# K1921VK028 register map
Vendor: NIIET; Series: K1921VKx; File version: 2.17
CPU: CM4 r0p1, little endian, MPU, FPU, 4 interrupt priority bits
Registers are 32-bit, read-write, reset 0x0 unless marked. A register's access mark holds for its fields unless they carry their own. Offsets are from the block's base; [hi:lo] are bit positions; lines under a group give offsets from that group; {n}, {i} and the like mark numbered series; 'fields as' and 'values as' point back to an identical list.

## SDFM — SDFM controller registers
Base 0x40075000
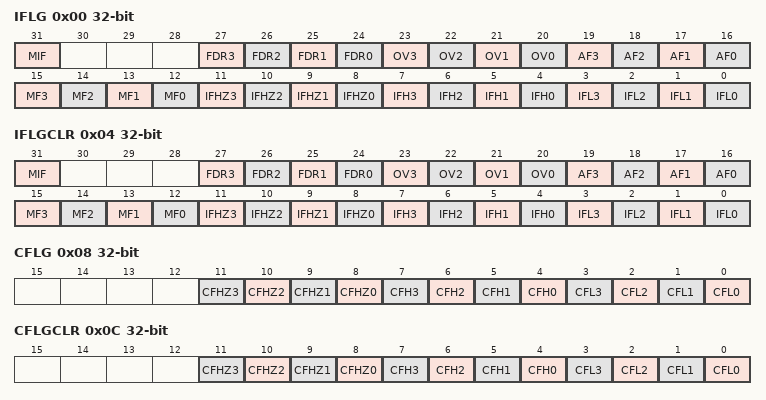
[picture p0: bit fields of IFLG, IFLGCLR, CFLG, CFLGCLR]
0x00 IFLG ro — Interrupt Flag Register
  [31] MIF — OR'ed flags OVx, MFx, IFHx, IFLx
  [n+24] FDR{n} (n=0..3) — FIFO{n} data ready flag
  [n+20] OV{n} (n=0..3) — Overflow FIFO{n} error flag
  [n+16] AF{n} (n=0..3) — New data available from filter {n}
  [n+12] MF{n} (n=0..3) — Modulator failure filter {n}
  [n+8] IFHZ{n} (n=0..3) — Comparator filter {n} output is equal to or above the zero level threshold
  [n+4] IFH{n} (n=0..3) — Comparator filter {n} output is equal to or above the high level threshold
  [n] IFL{n} (n=0..3) — Comparator filter {n} output is equal to or below the low level threshold
0x04 IFLGCLR wo — Clear Interrupt flag register
  [31] MIF — MIF flag clear bit
  [n+24] FDR{n} (n=0..3) — FIFO{n} data ready flag clear
  [n+20] OV{n} (n=0..3) — Overflow FIFO{n} error flag clear bit
  [n+16] AF{n} (n=0..3) — New data available from filter {n} clear bit
  [n+12] MF{n} (n=0..3) — Modulator failure filter {n} clear bit
  [n+8] IFHZ{n} (n=0..3) — Comparator filter {n} output is equal to or above the zero level threshold clear bit
  [n+4] IFH{n} (n=0..3) — Comparator filter {n} output is equal to or above the high level threshold clear bit
  [n] IFL{n} (n=0..3) — Comparator filter {n} output is equal to or below the low level threshold clear bit
0x08 CFLG ro — Comparator Flag Register
  [n+8] CFHZ{n} (n=0..3), [n+4] CFH{n} (n=0..3), [n] CFL{n} (n=0..3)
0x0C CFLGCLR wo — Comparator Flag Clear Register
  [n+8] CFHZ{n} (n=0..3), [n+4] CFH{n} (n=0..3), [n] CFL{n} (n=0..3)
0x10 CTL — Control Register
  [0] MIE — Master interrupt enable
0x14 MFILEN — Master Filter Enable Register
  [0] MFE — Master filter enable
{0x18+0x30*i} SD[{i}] (i=0..3) group
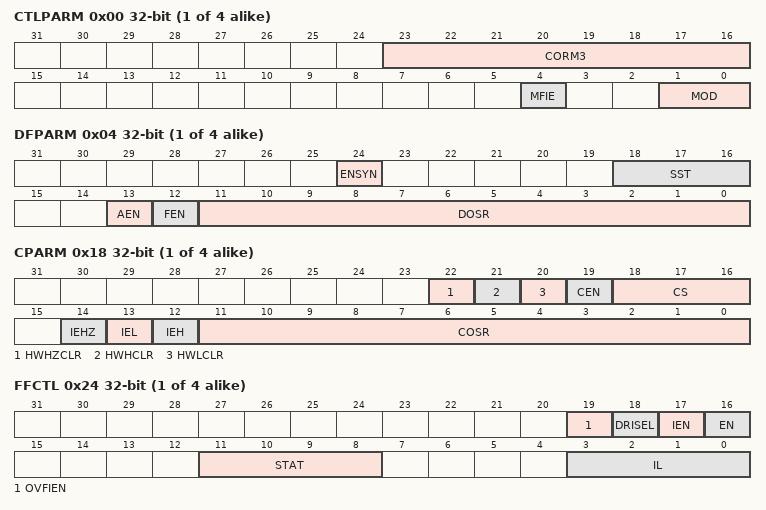
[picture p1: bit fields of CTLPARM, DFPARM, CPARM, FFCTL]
  0x00 CTLPARM — Filter Control Register
    [23:16] CORM3 — Clock out ratio for mode 3
    [4] MFIE — Modulator failure interrupt enable
    [1:0] MOD — Sigma Delta modulator IO mode
      0=Mode0SDR (single data rate); 1=Mode1DDR (double data rate); 2=Mode2Manchester (manchester coding); 3=Mode3HDR (half data rate)
  0x04 DFPARM — Data Filter Parameter Register
    [24] ENSYN — Enable syncronization for filter
    [18:16] SST — Data Filter structure
      0=FastSinc; 1=sinc 1-st order; 2=sinc 2-nd order; 3=sinc 3-rd order; 4=sinc 4-th order; 5=sinc 5-th order
    [13] AEN — Acknowledge enable
    [12] FEN — Filter enable
    [11:0] DOSR — Oversampling ratio
  0x08 DPARM — Shift Data Control Register
    [4:0] SH — Shift control
  0x0C CMPH — High Level Comparator Register
    [31:0] VAL — Unsigned high-level threshold comparator
  0x10 CMPHZ — Zero Level Comparator Register
    [31:0] VAL — Unsigned zero-level threshold comparator
  0x14 CMPL — Low Level Comparator Register
    [31:0] VAL — Unsigned low-level threshold comparator
  0x18 CPARM — Comparator Parameter register
    [22] HWHZCLR — Enable hardware clear zero threshold comparator exceed event
    [21] HWHCLR — Enable hardware clear high threshold comparator exceed event
    [20] HWLCLR — Enable hardware clear low threshold comparator exceed event
    [19] CEN — Comparator enable
    [18:16] CS — Comparator filter structure
      values as SD[0].DFPARM.SST
    [14] IEHZ — Zero-level interrupt enable
    [13] IEL — Low-level interrupt enable
    [12] IEH — High-level interrupt enable
    [11:0] COSR — Oversampling ratio for comparator
  0x1C DATA ro
    [31:0] VAL — Signed data value
  0x20 CDATA ro — Comparator Data Register
    [31:0] VAL — Comparator Data Value
  0x24 FFCTL — FIFO Configuration Register
    [19] OVFIEN — Overflow interrupt enable
    [18] DRISEL — Data Ready Int source
      0=AckData (acknowledge new data arrived); 1=FIFO data level
    [17] IEN — Interrupt FIFO enable
    [16] EN — Enable FIFO
    [11:8] STAT ro — Status FIFO level
    [3:0] IL — Interrupt level FIFO
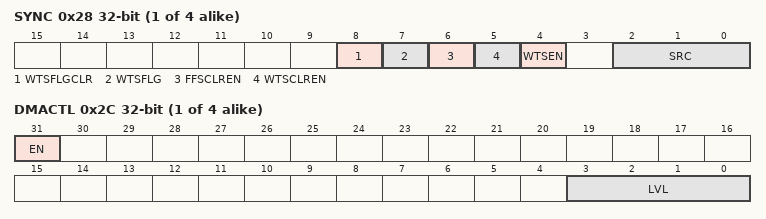
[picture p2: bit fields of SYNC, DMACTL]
  0x28 SYNC — Sync Control Register
    [8] WTSFLGCLR wo — Clear WTSFLG manually writing 1
    [7] WTSFLG ro — Event flag
    [6] FFSCLREN — Clear FIFO on event enable
    [5] WTSCLREN — WTSFLG cleared on FIFO data ready interrupt enable
    [4] WTSEN — wait for sync enable
    [2:0] SRC — Source syncronization selector for filter
      0=PWM012A (PWM0,1,2 A channel request); 1=PWM012B (PWM0,1,2 B channel request); 2=PWM345A (PWM3,4,5 A channel request); 3=PWM345B (PWM3,4,5 B channel request); 4=PWM6789A (PWM6,7,8,9 A channel request); 5=PWM6789B (PWM6,7,8,9 B channel request); 6=TMR0 (Timer 0 request); 7=TMR1 (Timer 1 request)
  0x2C DMACTL — DMA Control Register
    [31] EN — Enable DMA
    [3:0] LVL — Level FIFO data for DMA
